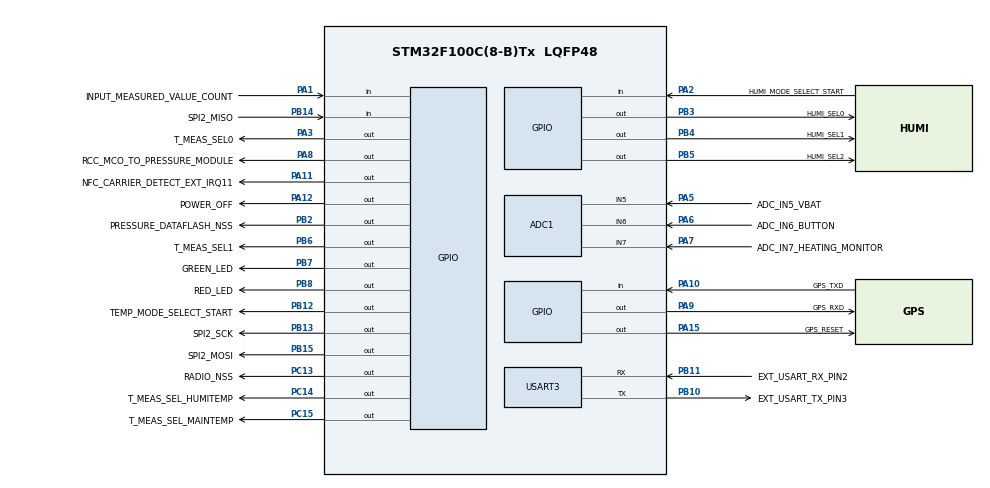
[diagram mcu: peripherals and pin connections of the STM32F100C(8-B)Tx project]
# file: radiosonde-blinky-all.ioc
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Mcu.Family=STM32F1
PB10.Mode=Asynchronous
PB14.GPIO_Label=SPI2_MISO
PA6.GPIO_Label=ADC_IN6_BUTTON
PB6.GPIO_Label=T_MEAS_SEL1
PB13.GPIO_Label=SPI2_SCK
PB11.Signal=USART3_RX
PB13.Signal=GPIO_Output
PB15.Signal=GPIO_Output
PC15-OSC32_OUT.GPIO_Label=T_MEAS_SEL_MAINTEMP
ProjectManager.StackSize=0x400
PA15.GPIO_Label=GPS_RESET
PA12.Signal=GPIO_Output
PB6.Signal=GPIO_Output
ADC1.Channel-0\#ChannelRegularConversion=ADC_CHANNEL_5
PB2.Signal=GPIO_Output
PB12.GPIO_Label=TEMP_MODE_SELECT_START
PA14.Mode=Serial_Wire
PA10.GPIO_Label=GPS_TXD
PB7.Signal=GPIO_Output
PA8.Signal=GPIO_Output
ADC1.SamplingTime-0\#ChannelRegularConversion=ADC_SAMPLETIME_1CYCLE_5
PB7.GPIO_Label=GREEN_LED
Mcu.Package=LQFP48
PA6.Signal=ADCx_IN6
PA2.GPIO_Label=HUMI_MODE_SELECT_START
PA10.Signal=GPIO_Input
PA15.Signal=GPIO_Output
PB5.GPIO_Label=HUMI_SEL2
PC14-OSC32_IN.GPIO_Label=T_MEAS_SEL_HUMITEMP
PB4.Signal=GPIO_Output
PA3.Signal=GPIO_Output
PB3.GPIO_Label=HUMI_SEL0
ADC1.Rank-0\#ChannelRegularConversion=1
SH.ADCx_IN6.0=ADC1_IN6,IN6
PA9.GPIO_Label=GPS_RXD
PB11.GPIO_Label=EXT_USART_RX_PIN2
PC13-TAMPER-RTC.Signal=GPIO_Output
PA11.GPIO_Label=NFC_CARRIER_DETECT_EXT_IRQ11
PC14-OSC32_IN.Signal=GPIO_Output
PA12.GPIO_Label=POWER_OFF
PA13.Signal=SYS_JTMS-SWDIO
PB8.GPIO_Label=RED_LED
PA8.GPIO_Label=RCC_MCO_TO_PRESSURE_MODULE
PB11.Mode=Asynchronous
ProjectManager.TargetToolchain=STM32CubeIDE
PB10.GPIO_Label=EXT_USART_TX_PIN3
SH.ADCx_IN7.0=ADC1_IN7,IN7
PA9.Signal=GPIO_Output
PC15-OSC32_OUT.Signal=GPIO_Output
PA1.Signal=GPIO_Input
PB10.Signal=USART3_TX
PB14.Signal=GPIO_Input
PA5.Signal=ADCx_IN5
board=custom
PC13-TAMPER-RTC.GPIO_Label=RADIO_NSS
RCC.APB2Freq_Value=8000000
PB4.GPIO_Label=HUMI_SEL1
PB15.GPIO_Label=SPI2_MOSI
PA1.GPIO_Label=INPUT_MEASURED_VALUE_COUNT
PA13.Mode=Serial_Wire
Mcu.Name=STM32F100C(8-B)Tx
PA2.Signal=GPIO_Input
PB3.Signal=GPIO_Output
PB5.Signal=GPIO_Output
PA7.GPIO_Label=ADC_IN7_HEATING_MONITOR
ADC1.master=1
PA5.GPIO_Label=ADC_IN5_VBAT
USART3.VirtualMode=VM_ASYNC
PA11.Signal=GPIO_Output
PA14.Signal=SYS_JTCK-SWCLK
PB2.GPIO_Label=PRESSURE_DATAFLASH_NSS
ProjectManager.HeapSize=0x200
SH.ADCx_IN5.0=ADC1_IN5,IN5
NVIC.PriorityGroup=NVIC_PRIORITYGROUP_4
ADC1.NbrOfConversionFlag=1
PB8.Signal=GPIO_Output
RCC.APB1Freq_Value=8000000
PB12.Signal=GPIO_Output
PA3.GPIO_Label=T_MEAS_SEL0
PA7.Signal=ADCx_IN7

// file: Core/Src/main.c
/* USER CODE BEGIN Header */
/**
  ******************************************************************************
  * @file           : main.c
  * @brief          : Main program body
  ******************************************************************************
  * @attention
  *
  * <h2><center>&copy; Copyright (c) 2021 STMicroelectronics.
  * All rights reserved.</center></h2>
  *
  * This software component is licensed by ST under BSD 3-Clause license,
  * the "License"; You may not use this file except in compliance with the
  * License. You may obtain a copy of the License at:
  *                        opensource.org/licenses/BSD-3-Clause
  *
  ******************************************************************************
  */
/* USER CODE END Header */
#include "main.h"

ADC_HandleTypeDef hadc1;

UART_HandleTypeDef huart3;

void SystemClock_Config(void);
static void MX_GPIO_Init(void);
static void MX_ADC1_Init(void);
static void MX_USART3_UART_Init(void);

int main(void)
{

  /* MCU Configuration--------------------------------------------------------*/

  /* Reset of all peripherals, Initializes the Flash interface and the Systick. */
  HAL_Init();

  /* Configure the system clock */
  SystemClock_Config();

  /* Initialize all configured peripherals */
  MX_GPIO_Init();
  MX_ADC1_Init();
  MX_USART3_UART_Init();

  /* Infinite loop */
  /* USER CODE BEGIN WHILE */
  while (1)
  {
	HAL_GPIO_WritePin(GPIOB, GPIO_PIN_7, GPIO_PIN_SET);
	HAL_GPIO_WritePin(GPIOB, GPIO_PIN_8, GPIO_PIN_RESET);
	HAL_Delay(100);
	HAL_GPIO_WritePin(GPIOB, GPIO_PIN_7, GPIO_PIN_RESET);
	HAL_GPIO_WritePin(GPIOB, GPIO_PIN_8, GPIO_PIN_SET);
	HAL_Delay(100);
    /* USER CODE END WHILE */

  }
}

void SystemClock_Config(void)
{
  RCC_OscInitTypeDef RCC_OscInitStruct = {0};
  RCC_ClkInitTypeDef RCC_ClkInitStruct = {0};
  RCC_PeriphCLKInitTypeDef PeriphClkInit = {0};

  /** Initializes the RCC Oscillators according to the specified parameters
  * in the RCC_OscInitTypeDef structure.
  */
  RCC_OscInitStruct.OscillatorType = RCC_OSCILLATORTYPE_HSI;
  RCC_OscInitStruct.HSIState = RCC_HSI_ON;
  RCC_OscInitStruct.HSICalibrationValue = RCC_HSICALIBRATION_DEFAULT;
  RCC_OscInitStruct.PLL.PLLState = RCC_PLL_NONE;
  if (HAL_RCC_OscConfig(&RCC_OscInitStruct) != HAL_OK)
  {
    Error_Handler();
  }
  /** Initializes the CPU, AHB and APB buses clocks
  */
  RCC_ClkInitStruct.ClockType = RCC_CLOCKTYPE_HCLK|RCC_CLOCKTYPE_SYSCLK
                              |RCC_CLOCKTYPE_PCLK1|RCC_CLOCKTYPE_PCLK2;
  RCC_ClkInitStruct.SYSCLKSource = RCC_SYSCLKSOURCE_HSI;
  RCC_ClkInitStruct.AHBCLKDivider = RCC_SYSCLK_DIV1;
  RCC_ClkInitStruct.APB1CLKDivider = RCC_HCLK_DIV1;
  RCC_ClkInitStruct.APB2CLKDivider = RCC_HCLK_DIV1;

  if (HAL_RCC_ClockConfig(&RCC_ClkInitStruct, FLASH_LATENCY_0) != HAL_OK)
  {
    Error_Handler();
  }
  PeriphClkInit.PeriphClockSelection = RCC_PERIPHCLK_ADC;
  PeriphClkInit.AdcClockSelection = RCC_ADCPCLK2_DIV2;
  if (HAL_RCCEx_PeriphCLKConfig(&PeriphClkInit) != HAL_OK)
  {
    Error_Handler();
  }
}

static void MX_ADC1_Init(void)
{

  ADC_ChannelConfTypeDef sConfig = {0};

  /** Common config
  */
  hadc1.Instance = ADC1;
  hadc1.Init.ScanConvMode = ADC_SCAN_DISABLE;
  hadc1.Init.ContinuousConvMode = DISABLE;
  hadc1.Init.DiscontinuousConvMode = DISABLE;
  hadc1.Init.ExternalTrigConv = ADC_SOFTWARE_START;
  hadc1.Init.DataAlign = ADC_DATAALIGN_RIGHT;
  hadc1.Init.NbrOfConversion = 1;
  if (HAL_ADC_Init(&hadc1) != HAL_OK)
  {
    Error_Handler();
  }
  /** Configure Regular Channel
  */
  sConfig.Channel = ADC_CHANNEL_5;
  sConfig.Rank = ADC_REGULAR_RANK_1;
  sConfig.SamplingTime = ADC_SAMPLETIME_1CYCLE_5;
  if (HAL_ADC_ConfigChannel(&hadc1, &sConfig) != HAL_OK)
  {
    Error_Handler();
  }

}

static void MX_USART3_UART_Init(void)
{

  huart3.Instance = USART3;
  huart3.Init.BaudRate = 115200;
  huart3.Init.WordLength = UART_WORDLENGTH_8B;
  huart3.Init.StopBits = UART_STOPBITS_1;
  huart3.Init.Parity = UART_PARITY_NONE;
  huart3.Init.Mode = UART_MODE_TX_RX;
  huart3.Init.HwFlowCtl = UART_HWCONTROL_NONE;
  huart3.Init.OverSampling = UART_OVERSAMPLING_16;
  if (HAL_UART_Init(&huart3) != HAL_OK)
  {
    Error_Handler();
  }

}

static void MX_GPIO_Init(void)
{
  GPIO_InitTypeDef GPIO_InitStruct = {0};

  /* GPIO Ports Clock Enable */
  __HAL_RCC_GPIOC_CLK_ENABLE();
  __HAL_RCC_GPIOA_CLK_ENABLE();
  __HAL_RCC_GPIOB_CLK_ENABLE();

  /*Configure GPIO pin Output Level */
  HAL_GPIO_WritePin(GPIOC, RADIO_NSS_Pin|T_MEAS_SEL_HUMITEMP_Pin|T_MEAS_SEL_MAINTEMP_Pin, GPIO_PIN_RESET);

  /*Configure GPIO pin Output Level */
  HAL_GPIO_WritePin(GPIOA, T_MEAS_SEL0_Pin|RCC_MCO_TO_PRESSURE_MODULE_Pin|GPS_RXD_Pin|NFC_CARRIER_DETECT_EXT_IRQ11_Pin
                          |POWER_OFF_Pin|GPS_RESET_Pin, GPIO_PIN_RESET);

  /*Configure GPIO pin Output Level */
  HAL_GPIO_WritePin(GPIOB, PRESSURE_DATAFLASH_NSS_Pin|TEMP_MODE_SELECT_START_Pin|SPI2_SCK_Pin|SPI2_MOSI_Pin
                          |HUMI_SEL0_Pin|HUMI_SEL1_Pin|HUMI_SEL2_Pin|T_MEAS_SEL1_Pin
                          |GREEN_LED_Pin|RED_LED_Pin, GPIO_PIN_RESET);

  /*Configure GPIO pins : RADIO_NSS_Pin T_MEAS_SEL_HUMITEMP_Pin T_MEAS_SEL_MAINTEMP_Pin */
  GPIO_InitStruct.Pin = RADIO_NSS_Pin|T_MEAS_SEL_HUMITEMP_Pin|T_MEAS_SEL_MAINTEMP_Pin;
  GPIO_InitStruct.Mode = GPIO_MODE_OUTPUT_PP;
  GPIO_InitStruct.Pull = GPIO_NOPULL;
  GPIO_InitStruct.Speed = GPIO_SPEED_FREQ_LOW;
  HAL_GPIO_Init(GPIOC, &GPIO_InitStruct);

  /*Configure GPIO pins : INPUT_MEASURED_VALUE_COUNT_Pin HUMI_MODE_SELECT_START_Pin GPS_TXD_Pin */
  GPIO_InitStruct.Pin = INPUT_MEASURED_VALUE_COUNT_Pin|HUMI_MODE_SELECT_START_Pin|GPS_TXD_Pin;
  GPIO_InitStruct.Mode = GPIO_MODE_INPUT;
  GPIO_InitStruct.Pull = GPIO_NOPULL;
  HAL_GPIO_Init(GPIOA, &GPIO_InitStruct);

  /*Configure GPIO pins : T_MEAS_SEL0_Pin RCC_MCO_TO_PRESSURE_MODULE_Pin GPS_RXD_Pin NFC_CARRIER_DETECT_EXT_IRQ11_Pin
                           POWER_OFF_Pin GPS_RESET_Pin */
  GPIO_InitStruct.Pin = T_MEAS_SEL0_Pin|RCC_MCO_TO_PRESSURE_MODULE_Pin|GPS_RXD_Pin|NFC_CARRIER_DETECT_EXT_IRQ11_Pin
                          |POWER_OFF_Pin|GPS_RESET_Pin;
  GPIO_InitStruct.Mode = GPIO_MODE_OUTPUT_PP;
  GPIO_InitStruct.Pull = GPIO_NOPULL;
  GPIO_InitStruct.Speed = GPIO_SPEED_FREQ_LOW;
  HAL_GPIO_Init(GPIOA, &GPIO_InitStruct);

  /*Configure GPIO pins : PRESSURE_DATAFLASH_NSS_Pin TEMP_MODE_SELECT_START_Pin SPI2_SCK_Pin SPI2_MOSI_Pin
                           HUMI_SEL0_Pin HUMI_SEL1_Pin HUMI_SEL2_Pin T_MEAS_SEL1_Pin
                           GREEN_LED_Pin RED_LED_Pin */
  GPIO_InitStruct.Pin = PRESSURE_DATAFLASH_NSS_Pin|TEMP_MODE_SELECT_START_Pin|SPI2_SCK_Pin|SPI2_MOSI_Pin
                          |HUMI_SEL0_Pin|HUMI_SEL1_Pin|HUMI_SEL2_Pin|T_MEAS_SEL1_Pin
                          |GREEN_LED_Pin|RED_LED_Pin;
  GPIO_InitStruct.Mode = GPIO_MODE_OUTPUT_PP;
  GPIO_InitStruct.Pull = GPIO_NOPULL;
  GPIO_InitStruct.Speed = GPIO_SPEED_FREQ_LOW;
  HAL_GPIO_Init(GPIOB, &GPIO_InitStruct);

  /*Configure GPIO pin : SPI2_MISO_Pin */
  GPIO_InitStruct.Pin = SPI2_MISO_Pin;
  GPIO_InitStruct.Mode = GPIO_MODE_INPUT;
  GPIO_InitStruct.Pull = GPIO_NOPULL;
  HAL_GPIO_Init(SPI2_MISO_GPIO_Port, &GPIO_InitStruct);

}

void Error_Handler(void)
{
  __disable_irq();
  while (1)
  {
  }
}

/************************ (C) COPYRIGHT STMicroelectronics *****END OF FILE****/
